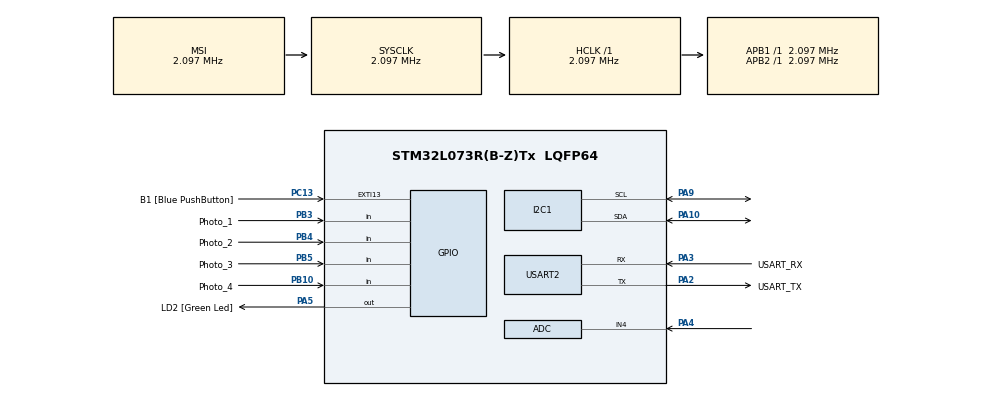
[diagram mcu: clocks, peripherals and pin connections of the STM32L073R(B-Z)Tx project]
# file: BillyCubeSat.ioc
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I2C1.Timing=0x00000608
Mcu.Family=STM32L0
Mcu.Name=STM32L073R(B-Z)Tx
Mcu.Package=LQFP64
NVIC.ADC1_COMP_IRQn=true\:0\:0\:false\:false\:true\:true\:true\:true
PA10.Mode=I2C
PA10.Signal=I2C1_SDA
PA13.GPIO_Label=TMS
PA13.Mode=Serial_Wire
PA13.Signal=SYS_SWDIO
PA14.GPIO_Label=TCK
PA14.Mode=Serial_Wire
PA14.Signal=SYS_SWCLK
PA2.GPIO_Label=USART_TX
PA2.Mode=Asynchronous
PA2.Signal=USART2_TX
PA3.GPIO_Label=USART_RX
PA3.Mode=Asynchronous
PA3.Signal=USART2_RX
PA4.Mode=IN4
PA4.Signal=ADC_IN4
PA5.GPIO_Label=LD2 [Green Led]
PA5.Signal=GPIO_Output
PA9.Mode=I2C
PA9.Signal=I2C1_SCL
PB10.GPIO_Label=Photo_4
PB10.Signal=GPIO_Input
PB3.GPIO_Label=Photo_1
PB3.Signal=GPIO_Input
PB4.GPIO_Label=Photo_2
PB4.Signal=GPIO_Input
PB5.GPIO_Label=Photo_3
PB5.Signal=GPIO_Input
PC13.GPIO_Label=B1 [Blue PushButton]
PC13.GPIO_ModeDefaultEXTI=GPIO_MODE_IT_FALLING
PC13.Signal=GPXTI13
PC14-OSC32_IN.Mode=LSE-External-Oscillator
PC14-OSC32_IN.Signal=RCC_OSC32_IN
PC15-OSC32_OUT.Mode=LSE-External-Oscillator
PC15-OSC32_OUT.Signal=RCC_OSC32_OUT
PH0-OSC_IN.GPIO_Label=MCO
PH0-OSC_IN.Mode=HSE-External-Clock-Source
PH0-OSC_IN.Signal=RCC_OSC_IN
ProjectManager.HeapSize=0x200
ProjectManager.StackSize=0x400
ProjectManager.TargetToolchain=CMake
RCC.AHBFreq_Value=2097000
RCC.APB1Freq_Value=2097000
RCC.APB1TimFreq_Value=2097000
RCC.APB2Freq_Value=2097000
RCC.APB2TimFreq_Value=2097000
RCC.HSE_VALUE=8000000
RCC.HSI16_VALUE=16000000
RCC.HSI48_VALUE=48000000
RCC.HSI_VALUE=16000000
RCC.MSI_VALUE=2097000
RCC.SYSCLKFreq_VALUE=2097000
RCC.VCOOutputFreq_Value=48000000
USART2.VirtualMode-Asynchronous=VM_ASYNC
board=NUCLEO-L073RZ

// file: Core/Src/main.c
/* USER CODE BEGIN Header */
/**
  ******************************************************************************
  * @file           : main.c
  * @brief          : Main program body
  ******************************************************************************
  * @attention
  *
  * Copyright (c) 2026 STMicroelectronics.
  * All rights reserved.
  *
  * This software is licensed under terms that can be found in the LICENSE file
  * in the root directory of this software component.
  * If no LICENSE file comes with this software, it is provided AS-IS.
  *
  ******************************************************************************
  */
/* USER CODE END Header */
#include "main.h"
#include "adc.h"
#include "i2c.h"
#include "usart.h"
#include "gpio.h"

/* USER CODE BEGIN Includes */
#include <stdio.h>
/* USER CODE END Includes */

void SystemClock_Config(void);

int main(void)
{

  /* MCU Configuration--------------------------------------------------------*/

  /* Reset of all peripherals, Initializes the Flash interface and the Systick. */
  HAL_Init();

  /* Configure the system clock */
  SystemClock_Config();

  /* Initialize all configured peripherals */
  MX_GPIO_Init();
  MX_USART2_UART_Init();
  MX_I2C1_Init();
  MX_ADC_Init();

  /* Infinite loop */
  /* USER CODE BEGIN WHILE */
  while (1)
  {
    HAL_ADC_Start_IT(&hadc);
    int16_t value = HAL_ADC_GetValue(&hadc);
    printf("%i\r\n", value);
    /* USER CODE END WHILE */

  }
}

void SystemClock_Config(void)
{
  RCC_OscInitTypeDef RCC_OscInitStruct = {0};
  RCC_ClkInitTypeDef RCC_ClkInitStruct = {0};
  RCC_PeriphCLKInitTypeDef PeriphClkInit = {0};

  /** Configure the main internal regulator output voltage
  */
  __HAL_PWR_VOLTAGESCALING_CONFIG(PWR_REGULATOR_VOLTAGE_SCALE1);

  /** Initializes the RCC Oscillators according to the specified parameters
  * in the RCC_OscInitTypeDef structure.
  */
  RCC_OscInitStruct.OscillatorType = RCC_OSCILLATORTYPE_MSI;
  RCC_OscInitStruct.MSIState = RCC_MSI_ON;
  RCC_OscInitStruct.MSICalibrationValue = 0;
  RCC_OscInitStruct.MSIClockRange = RCC_MSIRANGE_5;
  RCC_OscInitStruct.PLL.PLLState = RCC_PLL_NONE;
  if (HAL_RCC_OscConfig(&RCC_OscInitStruct) != HAL_OK)
  {
    Error_Handler();
  }

  /** Initializes the CPU, AHB and APB buses clocks
  */
  RCC_ClkInitStruct.ClockType = RCC_CLOCKTYPE_HCLK|RCC_CLOCKTYPE_SYSCLK
                              |RCC_CLOCKTYPE_PCLK1|RCC_CLOCKTYPE_PCLK2;
  RCC_ClkInitStruct.SYSCLKSource = RCC_SYSCLKSOURCE_MSI;
  RCC_ClkInitStruct.AHBCLKDivider = RCC_SYSCLK_DIV1;
  RCC_ClkInitStruct.APB1CLKDivider = RCC_HCLK_DIV1;
  RCC_ClkInitStruct.APB2CLKDivider = RCC_HCLK_DIV1;

  if (HAL_RCC_ClockConfig(&RCC_ClkInitStruct, FLASH_LATENCY_0) != HAL_OK)
  {
    Error_Handler();
  }
  PeriphClkInit.PeriphClockSelection = RCC_PERIPHCLK_USART2|RCC_PERIPHCLK_I2C1;
  PeriphClkInit.Usart2ClockSelection = RCC_USART2CLKSOURCE_PCLK1;
  PeriphClkInit.I2c1ClockSelection = RCC_I2C1CLKSOURCE_PCLK1;
  if (HAL_RCCEx_PeriphCLKConfig(&PeriphClkInit) != HAL_OK)
  {
    Error_Handler();
  }
}

/* USER CODE BEGIN 4 */
/**
* @brief  Retargets the C library printf function to the USART.
*/
int __io_putchar(int ch)
{
/* Custom implementation of fputc here */
HAL_UART_Transmit(&huart2, (uint8_t *)&ch, 1, 0xFFFF);
return ch;
}
/* USER CODE END 4 */

void Error_Handler(void)
{
  __disable_irq();
  while (1)
  {
  }
}
